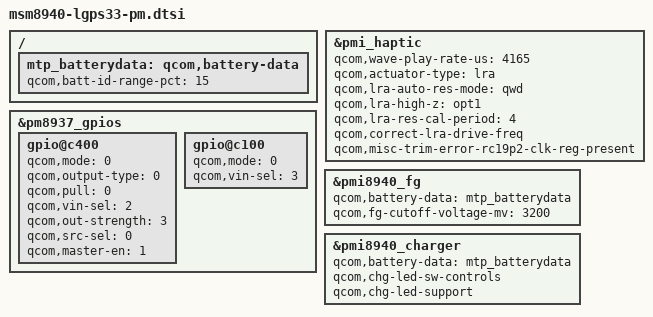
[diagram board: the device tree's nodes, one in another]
/*
 * Copyright (c) 2016, The Linux Foundation. All rights reserved.
 *
 * This program is free software; you can redistribute it and/or modify
 * it under the terms of the GNU General Public License version 2 and
 * only version 2 as published by the Free Software Foundation.
 *
 * This program is distributed in the hope that it will be useful,
 * but WITHOUT ANY WARRANTY; without even the implied warranty of
 * MERCHANTABILITY or FITNESS FOR A PARTICULAR PURPOSE.  See the
 * GNU General Public License for more details.
 */

&pmi_haptic{
	qcom,wave-play-rate-us = <4165>;
	qcom,actuator-type = "lra";
	qcom,lra-auto-res-mode="qwd";
	qcom,lra-high-z="opt1";
	qcom,lra-res-cal-period = <4>;
	qcom,correct-lra-drive-freq;
	qcom,misc-trim-error-rc19p2-clk-reg-present;
};

&pm8937_gpios {
	gpio@c400 {
		qcom,mode = <0>;
		qcom,output-type = <0>;
		qcom,pull = <0>;
		qcom,vin-sel = <2>;
		qcom,out-strength = <3>;
		qcom,src-sel = <0>;
		qcom,master-en = <1>;
		status = "okay";
	};
};

/* PM8937 GPIO configuration */
&pm8937_gpios {
	gpio@c100 {
		qcom,mode = <0>;
		qcom,vin-sel = <3>;
		status = "okay";
	};
};

/{
	mtp_batterydata: qcom,battery-data {
		qcom,batt-id-range-pct = <15>;
		#include "../../qcom/batterydata-itech-3000mah.dtsi"
		#include "../../qcom/batterydata-ascent-3450mAh.dtsi"
	};
};

&pmi8940_fg {
	qcom,battery-data = <&mtp_batterydata>;
	qcom,fg-cutoff-voltage-mv = <3200>; /* Temporary Fix */
};

&pmi8940_charger {
	qcom,battery-data = <&mtp_batterydata>;
	qcom,chg-led-sw-controls;
	qcom,chg-led-support;
};
